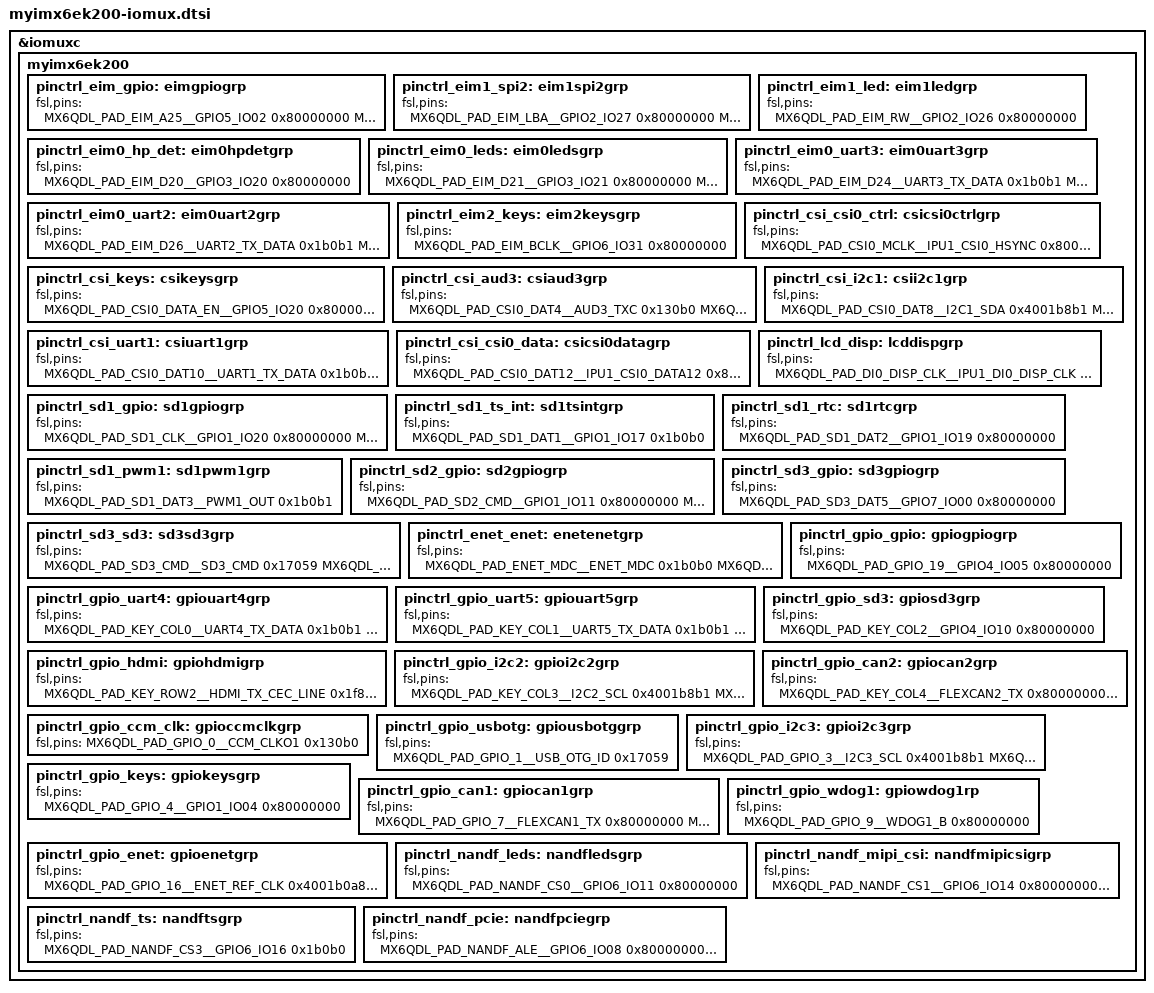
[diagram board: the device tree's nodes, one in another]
/*
 * MYZR	Technology	Co.,Ltd
 * http://www.myzr.com.cn
 * Tang	Bin	<tangb@myzr.com.cn>
 */

&iomuxc	{
	myimx6ek200	{
		pinctrl_eim_gpio: eimgpiogrp {
			fsl,pins = <
				MX6QDL_PAD_EIM_A25__GPIO5_IO02		0x80000000	/* GPIO, J7:4 */
				MX6QDL_PAD_EIM_D23__GPIO3_IO23		0x80000000	/* GPIO, J1:12 */
				MX6QDL_PAD_EIM_D28__GPIO3_IO28		0x80000000	/* GPIO, J1:8 */
				MX6QDL_PAD_EIM_D29__GPIO3_IO29		0x80000000	/* GPIO, J1:10 */
				MX6QDL_PAD_EIM_D30__GPIO3_IO30		0x80000000	/* GPIO, J21:12 */
			>;
		};
		pinctrl_eim1_spi2: eim1spi2grp	{
			fsl,pins = <
				MX6QDL_PAD_EIM_LBA__GPIO2_IO27		0x80000000	/* SPI2_CS1; J7:12 */
				MX6QDL_PAD_EIM_OE__ECSPI2_MISO		0x100b1
				MX6QDL_PAD_EIM_CS0__ECSPI2_SCLK		0x100b1
				MX6QDL_PAD_EIM_CS1__ECSPI2_MOSI		0x100b1
			>;
		};
		pinctrl_eim1_led: eim1ledgrp	{
			fsl,pins = <
				MX6QDL_PAD_EIM_RW__GPIO2_IO26		0x80000000	/* LED3, D8 */
			>;
		};
		/* pinctrl_eim_nc: eimncgrp	{
			fsl,pins = <
				MX6QDL_PAD_EIM_A16 ~ MX6QDL_PAD_EIM_A24
				MX6QDL_PAD_EIM_EB3
			>;
		}; */
		
		pinctrl_eim0_hp_det: eim0hpdetgrp	{
			fsl,pins = <
				MX6QDL_PAD_EIM_D20__GPIO3_IO20		0x80000000
			>;
		};
		pinctrl_eim0_leds: eim0ledsgrp	{
			fsl,pins = <
				MX6QDL_PAD_EIM_D21__GPIO3_IO21		0x80000000	/* LED2, D9 */
				MX6QDL_PAD_EIM_D22__GPIO3_IO22		0x80000000	/* LED1, D10 */
			>;
		};
		pinctrl_eim0_uart3: eim0uart3grp	{
			fsl,pins = <
				MX6QDL_PAD_EIM_D24__UART3_TX_DATA	0x1b0b1
				MX6QDL_PAD_EIM_D25__UART3_RX_DATA	0x1b0b1
				MX6QDL_PAD_EIM_D31__GPIO3_IO31		0x80000000	/* UART3, RS485 */
			>;
		};
		pinctrl_eim0_uart2: eim0uart2grp	{
			fsl,pins = <
				MX6QDL_PAD_EIM_D26__UART2_TX_DATA	0x1b0b1
				MX6QDL_PAD_EIM_D27__UART2_RX_DATA	0x1b0b1
			>;
		};
		
		pinctrl_eim2_keys: eim2keysgrp	{
			fsl,pins = <
				MX6QDL_PAD_EIM_BCLK__GPIO6_IO31		0x80000000	/* SW4, VOL+ */
			>;
		};
		/* pinctrl_eim2_nc: eim2ncgrp	{
			fsl,pins = <
				MX6QDL_PAD_EIM_WAIT
				MX6QDL_PAD_EIM_EB0 ~ MX6QDL_PAD_EIM_EB1
				MX6QDL_PAD_EIM_DA0 ~ MX6QDL_PAD_EIM_DA15
			>;
		}; */
		
		pinctrl_csi_csi0_ctrl: csicsi0ctrlgrp	{
			fsl,pins = <
				MX6QDL_PAD_CSI0_MCLK__IPU1_CSI0_HSYNC		0x80000000
				MX6QDL_PAD_CSI0_PIXCLK__IPU1_CSI0_PIXCLK	0x80000000
				MX6QDL_PAD_CSI0_VSYNC__IPU1_CSI0_VSYNC		0x80000000
			>;
		};
		pinctrl_csi_keys: csikeysgrp	{
			fsl,pins = <
				MX6QDL_PAD_CSI0_DATA_EN__GPIO5_IO20			0x80000000	/* SW5, VOL- */
			>;
		};
		pinctrl_csi_aud3: csiaud3grp	{
			fsl,pins = <
				MX6QDL_PAD_CSI0_DAT4__AUD3_TXC				0x130b0
				MX6QDL_PAD_CSI0_DAT5__AUD3_TXD				0x110b0
				MX6QDL_PAD_CSI0_DAT6__AUD3_TXFS				0x130b0
				MX6QDL_PAD_CSI0_DAT7__AUD3_RXD				0x130b0
			>;
		};
		pinctrl_csi_i2c1: csii2c1grp	{
			fsl,pins = <
				MX6QDL_PAD_CSI0_DAT8__I2C1_SDA				0x4001b8b1
				MX6QDL_PAD_CSI0_DAT9__I2C1_SCL				0x4001b8b1
			>;
		};
		pinctrl_csi_uart1: csiuart1grp	{
			fsl,pins = <
				MX6QDL_PAD_CSI0_DAT10__UART1_TX_DATA		0x1b0b1
				MX6QDL_PAD_CSI0_DAT11__UART1_RX_DATA		0x1b0b1
			>;
		};
		pinctrl_csi_csi0_data: csicsi0datagrp	{
			fsl,pins = <
				MX6QDL_PAD_CSI0_DAT12__IPU1_CSI0_DATA12		0x80000000
				MX6QDL_PAD_CSI0_DAT13__IPU1_CSI0_DATA13		0x80000000
				MX6QDL_PAD_CSI0_DAT14__IPU1_CSI0_DATA14		0x80000000
				MX6QDL_PAD_CSI0_DAT15__IPU1_CSI0_DATA15		0x80000000
				MX6QDL_PAD_CSI0_DAT16__IPU1_CSI0_DATA16		0x80000000
				MX6QDL_PAD_CSI0_DAT17__IPU1_CSI0_DATA17		0x80000000
				MX6QDL_PAD_CSI0_DAT18__IPU1_CSI0_DATA18		0x80000000
				MX6QDL_PAD_CSI0_DAT19__IPU1_CSI0_DATA19		0x80000000
			>;
		};
		
		pinctrl_lcd_disp: lcddispgrp	{
			fsl,pins = <
				MX6QDL_PAD_DI0_DISP_CLK__IPU1_DI0_DISP_CLK	0x10
				MX6QDL_PAD_DI0_PIN2__IPU1_DI0_PIN02			0x10
				MX6QDL_PAD_DI0_PIN3__IPU1_DI0_PIN03			0x10
				/* MX6QDL_PAD_DI0_PIN4				NC*/
				MX6QDL_PAD_DI0_PIN15__IPU1_DI0_PIN15		0x10	
				MX6QDL_PAD_DISP0_DAT0__IPU1_DISP0_DATA00	0x10
				MX6QDL_PAD_DISP0_DAT1__IPU1_DISP0_DATA01	0x10
				MX6QDL_PAD_DISP0_DAT2__IPU1_DISP0_DATA02	0x10
				MX6QDL_PAD_DISP0_DAT3__IPU1_DISP0_DATA03	0x10
				MX6QDL_PAD_DISP0_DAT4__IPU1_DISP0_DATA04	0x10
				MX6QDL_PAD_DISP0_DAT5__IPU1_DISP0_DATA05	0x10
				MX6QDL_PAD_DISP0_DAT6__IPU1_DISP0_DATA06	0x10
				MX6QDL_PAD_DISP0_DAT7__IPU1_DISP0_DATA07	0x10
				MX6QDL_PAD_DISP0_DAT8__IPU1_DISP0_DATA08	0x10
				MX6QDL_PAD_DISP0_DAT9__IPU1_DISP0_DATA09	0x10
				MX6QDL_PAD_DISP0_DAT10__IPU1_DISP0_DATA10	0x10
				MX6QDL_PAD_DISP0_DAT11__IPU1_DISP0_DATA11	0x10
				MX6QDL_PAD_DISP0_DAT12__IPU1_DISP0_DATA12	0x10
				MX6QDL_PAD_DISP0_DAT13__IPU1_DISP0_DATA13	0x10
				MX6QDL_PAD_DISP0_DAT14__IPU1_DISP0_DATA14	0x10
				MX6QDL_PAD_DISP0_DAT15__IPU1_DISP0_DATA15	0x10
				MX6QDL_PAD_DISP0_DAT16__IPU1_DISP0_DATA16	0x10
				MX6QDL_PAD_DISP0_DAT17__IPU1_DISP0_DATA17	0x10
				MX6QDL_PAD_DISP0_DAT18__IPU1_DISP0_DATA18	0x10
				MX6QDL_PAD_DISP0_DAT19__IPU1_DISP0_DATA19	0x10
				MX6QDL_PAD_DISP0_DAT20__IPU1_DISP0_DATA20	0x10
				MX6QDL_PAD_DISP0_DAT21__IPU1_DISP0_DATA21	0x10
				MX6QDL_PAD_DISP0_DAT22__IPU1_DISP0_DATA22	0x10
				MX6QDL_PAD_DISP0_DAT23__IPU1_DISP0_DATA23	0x10
			>;
		};
		
		pinctrl_sd1_gpio: sd1gpiogrp	{
			fsl,pins = <
				/* MX6QDL_PAD_SD1_CMD			NC */
				MX6QDL_PAD_SD1_CLK__GPIO1_IO20		0x80000000	/* GPIO, J4:8 */
				MX6QDL_PAD_SD1_DAT0__GPIO1_IO16		0x80000000	/* GPIO, J14:18 */
			>;
		};
		pinctrl_sd1_ts_int: sd1tsintgrp	{
			fsl,pins = <
				MX6QDL_PAD_SD1_DAT1__GPIO1_IO17		0x1b0b0
			>;
		};
		pinctrl_sd1_rtc: sd1rtcgrp	{
			fsl,pins = <
				MX6QDL_PAD_SD1_DAT2__GPIO1_IO19		0x80000000	/* RTC GPIO */
			>;
		};
		pinctrl_sd1_pwm1: sd1pwm1grp	{
			fsl,pins = <
				MX6QDL_PAD_SD1_DAT3__PWM1_OUT		0x1b0b1		/* backlight */
			>;
		};

		pinctrl_sd2_gpio: sd2gpiogrp	{
			fsl,pins = <
				MX6QDL_PAD_SD2_CMD__GPIO1_IO11		0x80000000	/* GPIO, J4:13 */
				MX6QDL_PAD_SD2_CLK__GPIO1_IO10		0x80000000	/* GPIO, J4:7 */
				MX6QDL_PAD_SD2_DAT0__GPIO1_IO15		0x80000000	/* GPIO, J4:3 */
				MX6QDL_PAD_SD2_DAT1__GPIO1_IO14		0x80000000	/* GPIO, J4:5 */
				MX6QDL_PAD_SD2_DAT2__GPIO1_IO13		0x80000000	/* GPIO, J4:9 */
				MX6QDL_PAD_SD2_DAT3__GPIO1_IO12		0x80000000	/* GPIO, J4:11 */
			>;
		};
		
		pinctrl_sd3_gpio: sd3gpiogrp	{
			fsl,pins = <
				/* MX6QDL_PAD_SD3_DAT4			NC */
				/* MX6QDL_PAD_SD3_DAT6			NC */
				/* MX6QDL_PAD_SD3_DAT7			NC */
				MX6QDL_PAD_SD3_DAT5__GPIO7_IO00		0x80000000	/* GPIO, J21:11 */
			>;
		};
		pinctrl_sd3_sd3: sd3sd3grp	{
			fsl,pins = <
				MX6QDL_PAD_SD3_CMD__SD3_CMD			0x17059
				MX6QDL_PAD_SD3_CLK__SD3_CLK			0x10059
				MX6QDL_PAD_SD3_DAT0__SD3_DATA0		0x17059
				MX6QDL_PAD_SD3_DAT1__SD3_DATA1		0x17059
				MX6QDL_PAD_SD3_DAT2__SD3_DATA2		0x17059
				MX6QDL_PAD_SD3_DAT3__SD3_DATA3		0x17059
				MX6QDL_PAD_SD3_RST__GPIO7_IO08		0x80000000	/* W/P */
			>;
		};
		
		pinctrl_enet_enet: enetenetgrp	{
			fsl,pins = <
				MX6QDL_PAD_ENET_MDC__ENET_MDC		0x1b0b0
				MX6QDL_PAD_ENET_MDIO__ENET_MDIO		0x1b0b0
				MX6QDL_PAD_ENET_CRS_DV__ENET_RX_EN	0x1b0b0
				MX6QDL_PAD_ENET_REF_CLK__GPIO1_IO23	0x80000000	/* RST */
				MX6QDL_PAD_ENET_RX_ER__ENET_RX_ER	0x1b0b0
				MX6QDL_PAD_ENET_TX_EN__ENET_TX_EN	0x1b0b0
				MX6QDL_PAD_ENET_RXD0__ENET_RX_DATA0	0x1b0b0
				MX6QDL_PAD_ENET_RXD1__ENET_RX_DATA1	0x1b0b0
				MX6QDL_PAD_ENET_TXD0__ENET_TX_DATA0	0x1b0b0
				MX6QDL_PAD_ENET_TXD1__ENET_TX_DATA1	0x1b0b0
			>;
		};
		
		pinctrl_gpio_gpio: gpiogpiogrp	{
			fsl,pins = <
				/* MX6QDL_PAD_GPIO_2				NC */
				/* MX6QDL_PAD_GPIO_5				NC */
				/* MX6QDL_PAD_GPIO_17				NC */
				MX6QDL_PAD_GPIO_19__GPIO4_IO05		0x80000000	/* GPIO, J7:3 */
			>;
		};
		pinctrl_gpio_uart4: gpiouart4grp	{
			fsl,pins = <
				MX6QDL_PAD_KEY_COL0__UART4_TX_DATA	0x1b0b1
				MX6QDL_PAD_KEY_ROW0__UART4_RX_DATA	0x1b0b1
			>;
		};
		pinctrl_gpio_uart5: gpiouart5grp	{
			fsl,pins = <
				MX6QDL_PAD_KEY_COL1__UART5_TX_DATA	0x1b0b1
				MX6QDL_PAD_KEY_ROW1__UART5_RX_DATA	0x1b0b1
			>;
		};
		pinctrl_gpio_sd3: gpiosd3grp	{
			fsl,pins = <
				MX6QDL_PAD_KEY_COL2__GPIO4_IO10		0x80000000	/* SD3, CD */
			>;
		};
		pinctrl_gpio_hdmi: gpiohdmigrp	{
			fsl,pins = <
				MX6QDL_PAD_KEY_ROW2__HDMI_TX_CEC_LINE	0x1f8b0
			>;
		};
		pinctrl_gpio_i2c2: gpioi2c2grp	{
			fsl,pins = <
				MX6QDL_PAD_KEY_COL3__I2C2_SCL		0x4001b8b1
				MX6QDL_PAD_KEY_ROW3__I2C2_SDA		0x4001b8b1
				>;
		};
		pinctrl_gpio_can2: gpiocan2grp	{
			fsl,pins = <
				MX6QDL_PAD_KEY_COL4__FLEXCAN2_TX	0x80000000
				MX6QDL_PAD_KEY_ROW4__FLEXCAN2_RX	0x80000000
				>;
		};
		pinctrl_gpio_ccm_clk: gpioccmclkgrp	{
			fsl,pins = <
				MX6QDL_PAD_GPIO_0__CCM_CLKO1		0x130b0
			>;
		};
		pinctrl_gpio_usbotg: gpiousbotggrp	{
			fsl,pins = <
				MX6QDL_PAD_GPIO_1__USB_OTG_ID		0x17059		/* OTG_ID */
			>;
		};
		pinctrl_gpio_i2c3: gpioi2c3grp	{
			fsl,pins = <
				MX6QDL_PAD_GPIO_3__I2C3_SCL			0x4001b8b1
				MX6QDL_PAD_GPIO_6__I2C3_SDA			0x4001b8b1
			>;
		};
		pinctrl_gpio_keys: gpiokeysgrp	{
			fsl,pins = <
				MX6QDL_PAD_GPIO_4__GPIO1_IO04		0x80000000	/* SW3, WAKEUP */
			>;
		};
		pinctrl_gpio_can1: gpiocan1grp	{
			fsl,pins = <
				MX6QDL_PAD_GPIO_7__FLEXCAN1_TX		0x80000000
				MX6QDL_PAD_GPIO_8__FLEXCAN1_RX		0x80000000
			>;
		};
		pinctrl_gpio_wdog1: gpiowdog1rp	{
			fsl,pins = <
				MX6QDL_PAD_GPIO_9__WDOG1_B			0x80000000
			>;
		};
		pinctrl_gpio_enet: gpioenetgrp	{
			fsl,pins = <
				MX6QDL_PAD_GPIO_16__ENET_REF_CLK	0x4001b0a8
				MX6QDL_PAD_GPIO_18__GPIO7_IO13		0x000b1		/* ENET, INT */
			>;
		};

		pinctrl_nandf_leds: nandfledsgrp	{
			fsl,pins = <
				MX6QDL_PAD_NANDF_CS0__GPIO6_IO11	0x80000000	/* LED4, D7 */
			>;
		};
		pinctrl_nandf_mipi_csi: nandfmipicsigrp	{
			fsl,pins = <
				MX6QDL_PAD_NANDF_CS1__GPIO6_IO14	0x80000000	/* MIPI */
				MX6QDL_PAD_NANDF_CS2__GPIO6_IO15	0x80000000	/* MIPI */
			>;
		};
		pinctrl_nandf_ts: nandftsgrp	{
			fsl,pins = <
				MX6QDL_PAD_NANDF_CS3__GPIO6_IO16	0x1b0b0		/* TS, RST */
			>;
		};
		pinctrl_nandf_pcie: nandfpciegrp	{
			fsl,pins = <
				MX6QDL_PAD_NANDF_ALE__GPIO6_IO08	0x80000000
				MX6QDL_PAD_NANDF_CLE__GPIO6_IO07	0x80000000
				MX6QDL_PAD_NANDF_WP_B__GPIO6_IO09	0x80000000
			>;
		};
		/* pinctrl_nandf_nc: nandfncgrp	{
			fsl,pins = <
				MX6QDL_PAD_NANDF_RB0
				MX6QDL_PAD_NANDF_D0 ~ MX6QDL_PAD_NANDF_D7
			>;
		}; */
		
		/* pinctrl_rgmii_nc: rgmiincgrp	{
			fsl,pins = <
				MX6QDL_PAD_RGMII_*
			>;
		}; */
	};
};
